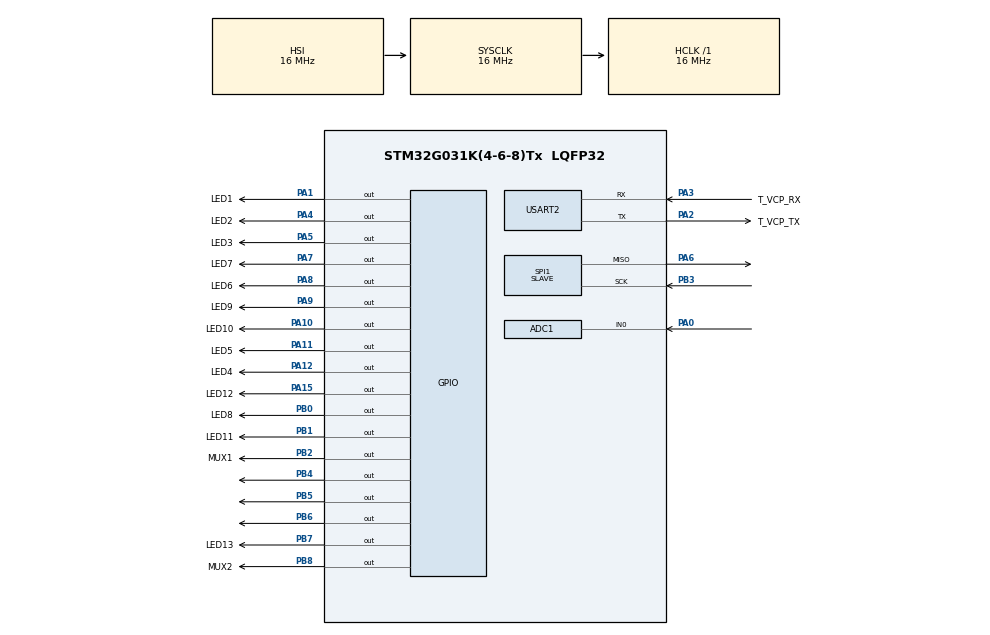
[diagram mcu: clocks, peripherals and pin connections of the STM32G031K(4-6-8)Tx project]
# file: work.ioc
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ADC1.Channel-0\#ChannelRegularConversion=ADC_CHANNEL_0
ADC1.ExternalTrigConv=ADC_EXTERNALTRIG_T3_TRGO
ADC1.NbrOfConversion=1
ADC1.NbrOfConversionFlag=1
ADC1.Rank-0\#ChannelRegularConversion=1
ADC1.SamplingTime-0\#ChannelRegularConversion=ADC_SAMPLINGTIME_COMMON_1
ADC1.SamplingTimeCommon1=ADC_SAMPLETIME_1CYCLE_5
ADC1.SelectedChannel=ADC_CHANNEL_0
ADC1.Sequencer=FULLY_CONFIGURABLE
ADC1.master=1
Mcu.Family=STM32G0
Mcu.Name=STM32G031K(4-6-8)Tx
Mcu.Package=LQFP32
NVIC.SPI1_IRQn=true\:0\:0\:false\:false\:true\:true\:true\:true
PA0.Mode=IN0
PA0.Signal=ADC1_IN0
PA1.GPIO_Label=LED1
PA1.Signal=GPIO_Output
PA10.GPIO_Label=LED10
PA10.Signal=GPIO_Output
PA11\ [PA9].GPIO_Label=LED5
PA11\ [PA9].Signal=GPIO_Output
PA12\ [PA10].GPIO_Label=LED4
PA12\ [PA10].Signal=GPIO_Output
PA15.GPIO_Label=LED12
PA15.Signal=GPIO_Output
PA2.GPIO_Label=T_VCP_TX
PA2.GPIO_PuPd=GPIO_PULLUP
PA2.Mode=Asynchronous
PA2.Signal=USART2_TX
PA3.GPIO_Label=T_VCP_RX
PA3.GPIO_PuPd=GPIO_PULLUP
PA3.Mode=Asynchronous
PA3.Signal=USART2_RX
PA4.GPIO_Label=LED2
PA4.Signal=GPIO_Output
PA5.GPIO_Label=LED3
PA5.Signal=GPIO_Output
PA6.Mode=TX_Only_Simplex_Unidirect_Slave
PA6.Signal=SPI1_MISO
PA7.GPIO_Label=LED7
PA7.Signal=GPIO_Output
PA8.GPIO_Label=LED6
PA8.Signal=GPIO_Output
PA9.GPIO_Label=LED9
PA9.Signal=GPIO_Output
PB0.GPIO_Label=LED8
PB0.Signal=GPIO_Output
PB1.GPIO_Label=LED11
PB1.Signal=GPIO_Output
PB2.GPIO_Label=MUX1
PB2.PinState=GPIO_PIN_SET
PB2.Signal=GPIO_Output
PB3.Mode=TX_Only_Simplex_Unidirect_Slave
PB3.Signal=SPI1_SCK
PB4.Signal=GPIO_Output
PB5.Signal=GPIO_Output
PB6.Signal=GPIO_Output
PB7.GPIO_Label=LED13
PB7.Signal=GPIO_Output
PB8.GPIO_Label=MUX2
PB8.PinState=GPIO_PIN_SET
PB8.Signal=GPIO_Output
ProjectManager.HeapSize=0x200
ProjectManager.StackSize=0x400
ProjectManager.TargetToolchain=MDK-ARM V5.32
RCC.ADCFreq_Value=16000000
RCC.AHBFreq_Value=16000000
RCC.CortexFreq_Value=16000000
RCC.EXTERNAL_CLOCK_VALUE=12288000
RCC.HCLKFreq_Value=16000000
RCC.HSE_VALUE=8000000
RCC.HSI_VALUE=16000000
RCC.LSE_VALUE=32768
RCC.SYSCLKFreq_VALUE=16000000
RCC.VCOOutputFreq_Value=128000000
SPI1.Direction=SPI_DIRECTION_2LINES
SPI1.Mode=SPI_MODE_SLAVE
SPI1.VirtualType=VM_SLAVE
TIM3.Period=1000-1
TIM3.Prescaler=16-1
TIM3.TIM_MasterOutputTrigger=TIM_TRGO_UPDATE
USART2.VirtualMode-Asynchronous=VM_ASYNC
USART2.WordLength=WORDLENGTH_8B
VP_TIM3_VS_ClockSourceINT.Mode=Internal
board=NUCLEO-G031K8

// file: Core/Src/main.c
/* USER CODE BEGIN Header */
/**
  ******************************************************************************
  * @file           : main.c
  * @brief          : Main program body
  ******************************************************************************
  * @attention
  *
  * Copyright (c) 2026 STMicroelectronics.
  * All rights reserved.
  *
  * This software is licensed under terms that can be found in the LICENSE file
  * in the root directory of this software component.
  * If no LICENSE file comes with this software, it is provided AS-IS.
  *
  ******************************************************************************
  */
/* USER CODE END Header */
#include "main.h"
#include "adc.h"
#include "spi.h"
#include "tim.h"
#include "usart.h"
#include "gpio.h"

/* USER CODE BEGIN Includes */
#include "my_adc.h"
#include "leds.h"
/* USER CODE END Includes */

void SystemClock_Config(void);

int main(void)
{

  /* MCU Configuration--------------------------------------------------------*/

  /* Reset of all peripherals, Initializes the Flash interface and the Systick. */
  HAL_Init();

  /* Configure the system clock */
  SystemClock_Config();

  /* Initialize all configured peripherals */
  MX_GPIO_Init();
  MX_ADC1_Init();
  MX_TIM3_Init();
  MX_USART2_UART_Init();
  MX_SPI1_Init();
  /* USER CODE BEGIN 2 */
	HAL_TIM_Base_Start(&htim3);
	HAL_ADC_Start(&hadc1);
  /* USER CODE END 2 */

  /* Infinite loop */
  while (1)
  {

    /* USER CODE BEGIN 3 */
		read_all_batteries();
		led_set_balancing(voltages);
  }
  /* USER CODE END 3 */
}

void SystemClock_Config(void)
{
  RCC_OscInitTypeDef RCC_OscInitStruct = {0};
  RCC_ClkInitTypeDef RCC_ClkInitStruct = {0};

  /** Configure the main internal regulator output voltage
  */
  HAL_PWREx_ControlVoltageScaling(PWR_REGULATOR_VOLTAGE_SCALE1);

  /** Initializes the RCC Oscillators according to the specified parameters
  * in the RCC_OscInitTypeDef structure.
  */
  RCC_OscInitStruct.OscillatorType = RCC_OSCILLATORTYPE_HSI;
  RCC_OscInitStruct.HSIState = RCC_HSI_ON;
  RCC_OscInitStruct.HSIDiv = RCC_HSI_DIV1;
  RCC_OscInitStruct.HSICalibrationValue = RCC_HSICALIBRATION_DEFAULT;
  RCC_OscInitStruct.PLL.PLLState = RCC_PLL_NONE;
  if (HAL_RCC_OscConfig(&RCC_OscInitStruct) != HAL_OK)
  {
    Error_Handler();
  }

  /** Initializes the CPU, AHB and APB buses clocks
  */
  RCC_ClkInitStruct.ClockType = RCC_CLOCKTYPE_HCLK|RCC_CLOCKTYPE_SYSCLK
                              |RCC_CLOCKTYPE_PCLK1;
  RCC_ClkInitStruct.SYSCLKSource = RCC_SYSCLKSOURCE_HSI;
  RCC_ClkInitStruct.AHBCLKDivider = RCC_SYSCLK_DIV1;
  RCC_ClkInitStruct.APB1CLKDivider = RCC_HCLK_DIV1;

  if (HAL_RCC_ClockConfig(&RCC_ClkInitStruct, FLASH_LATENCY_0) != HAL_OK)
  {
    Error_Handler();
  }
}

void Error_Handler(void)
{
  __disable_irq();
  while (1)
  {
  }
}
